# ECC_AGG_R5SS1_CORE1_ECC_AGG_R5SS1_CORE1 register map
Vendor: Texas Instruments
Peripheral module from a debugger description file (folder AM263).
Registers are 32-bit, read-write, reset 0x0 unless marked. A register's access mark holds for its fields unless they carry their own. Offsets are as the file gives them; lines under a group give offsets from that group; [hi:lo] are bit positions; {n}, {i} and the like mark numbered series; 'fields as' and 'values as' point back to an identical list; <NAME> marks a mode.

## ECC_AGG_R5SS1_CORE1_ECC_AGG_R5SS1_CORE1
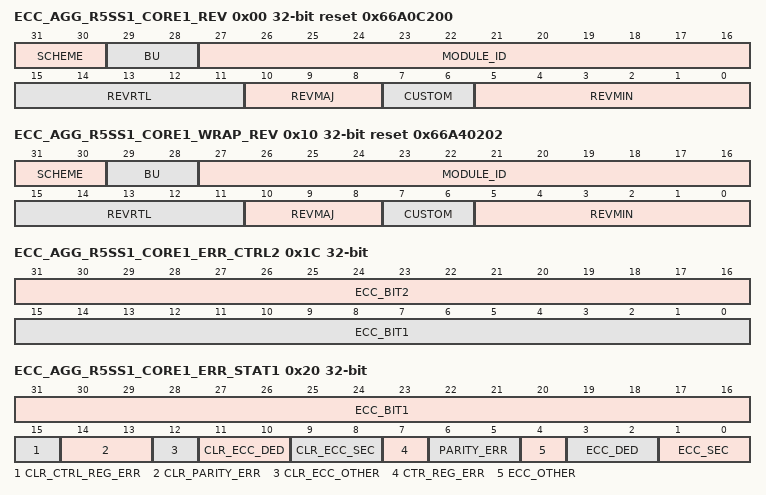
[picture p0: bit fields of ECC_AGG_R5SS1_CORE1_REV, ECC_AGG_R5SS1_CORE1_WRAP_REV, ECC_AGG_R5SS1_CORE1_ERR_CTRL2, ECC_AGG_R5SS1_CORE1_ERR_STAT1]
0x00 ECC_AGG_R5SS1_CORE1_REV ro reset 0x66A0C200
  [31:30] SCHEME
  [29:28] BU
  [27:16] MODULE_ID
  [15:11] REVRTL — RTL version
  [10:8] REVMAJ — Major version
  [7:6] CUSTOM — Custom version
  [5:0] REVMIN — Minor version
0x08 ECC_AGG_R5SS1_CORE1_VECTOR 24-bit access per field
  [24] RD_SVBUS_DONE ro — Status to indicate if read on serial VBUS is complete
  [23:16] RD_SVBUS_ADDRESS rw — Read address
  [15] RD_SVBUS rw — Write 1 to trigger a read on the serial VBUS
  [10:0] ECC_VECTOR rw — Value written to select the corresponding ECC RAM for control or status
0x0C ECC_AGG_R5SS1_CORE1_STAT 16-bit ro reset 0x1C
  [10:0] NUM_RAMS — Indicates the number of RAMS serviced by the ECC aggregator
0x10 ECC_AGG_R5SS1_CORE1_WRAP_REV ro reset 0x66A40202
  fields as ECC_AGG_R5SS1_CORE1_REV
0x14 ECC_AGG_R5SS1_CORE1_CTRL 8-bit reset 0x187
  [8] CHECK_SVBUS_TIMEOUT — check for svbus timeout errors
  [7] CHECK_PARITY — check for parity errors
  [6] ERROR_ONCE — Force Error only once
  [5] FORCE_N_ROW — Force Error on any RAM read
  [4] FORCE_DED — Force Double Bit Error
  [3] FORCE_SEC — Force Single Bit Error
  [2] ENABLE_RMW
  [1] ECC_CHECK — Enable ECC check
  [0] ECC_ENABLE — Enable ECC
0x18 ECC_AGG_R5SS1_CORE1_ERR_CTRL1
  [31:0] ECC_ROW — Row address where single or double-bit error needs to be applied. This is ignored if force_n_row is set
0x1C ECC_AGG_R5SS1_CORE1_ERR_CTRL2
  [31:16] ECC_BIT2 — Data bit that needs to be flipped if double bit error needs to be forced
  [15:0] ECC_BIT1 — Data bit that needs to be flipped when force_sec is set
0x20 ECC_AGG_R5SS1_CORE1_ERR_STAT1 access not given
  [31:16] ECC_BIT1 ro — Data bit that corresponds to the single-bit error
  [15] CLR_CTRL_REG_ERR rw — Clear control reg error Error Status, you must also re write the contorl ergister itself to clear this
  [14:13] CLR_PARITY_ERR — Clear parity Error Status (access RW DECR)
  [12] CLR_ECC_OTHER rw — Clear other Error Status
  [11:10] CLR_ECC_DED — Clear Double Bit Error Status (access RW DECR)
  [9:8] CLR_ECC_SEC — Clear Single Bit Error Status (access RW DECR)
  [7] CTR_REG_ERR rw — control register error pending, Level interrupt
  [6:5] PARITY_ERR rw — Level parity error Error Status
  [4] ECC_OTHER rw — successive single-bit errors have occurred while a writeback is still pending, Level interrupt
  [3:2] ECC_DED — Level Double Bit Error Status (access RW INCR)
  [1:0] ECC_SEC — Level Single Bit Error Status (access RW INCR)
0x24 ECC_AGG_R5SS1_CORE1_ERR_STAT2 ro
  [31:0] ECC_ROW — Row address where the single or double-bit error has occurred
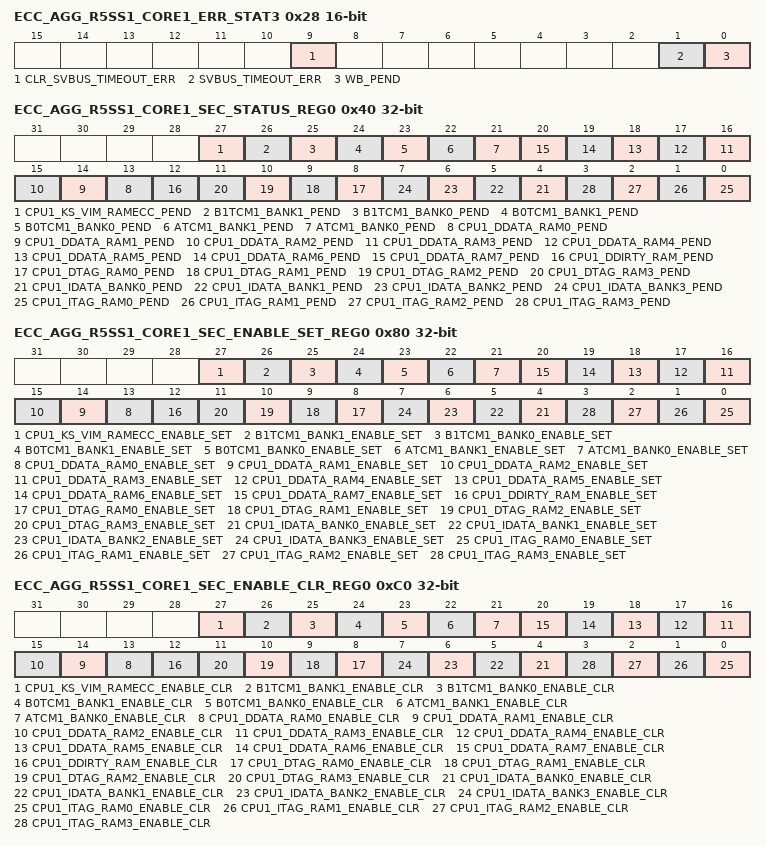
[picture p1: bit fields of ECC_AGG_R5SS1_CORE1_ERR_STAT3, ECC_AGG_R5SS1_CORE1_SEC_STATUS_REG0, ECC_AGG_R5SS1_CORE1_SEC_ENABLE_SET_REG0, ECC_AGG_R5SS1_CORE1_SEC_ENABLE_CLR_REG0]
0x28 ECC_AGG_R5SS1_CORE1_ERR_STAT3 16-bit access per field
  [9] CLR_SVBUS_TIMEOUT_ERR rw — Clear svbus timeout Error Status
  [1] SVBUS_TIMEOUT_ERR rw — Level svbus timeout error Error Status
  [0] WB_PEND ro — delayed write back pending Status
0x3C ECC_AGG_R5SS1_CORE1_SEC_EOI_REG size not given
  [0] EOI_WR — EOI Register
0x40 ECC_AGG_R5SS1_CORE1_SEC_STATUS_REG0
  [27] CPU1_KS_VIM_RAMECC_PEND — Interrupt Pending Status for cpu1_ks_vim_ramecc_pend
  [26] B1TCM1_BANK1_PEND — Interrupt Pending Status for b1tcm1_bank1_pend
  [25] B1TCM1_BANK0_PEND — Interrupt Pending Status for b1tcm1_bank0_pend
  [24] B0TCM1_BANK1_PEND — Interrupt Pending Status for b0tcm1_bank1_pend
  [23] B0TCM1_BANK0_PEND — Interrupt Pending Status for b0tcm1_bank0_pend
  [22] ATCM1_BANK1_PEND — Interrupt Pending Status for atcm1_bank1_pend
  [21] ATCM1_BANK0_PEND — Interrupt Pending Status for atcm1_bank0_pend
  [n+13] CPU1_DDATA_RAM{n}_PEND (n=0..7) — Interrupt Pending Status for cpu1_ddata_ram{n}_pend
  [12] CPU1_DDIRTY_RAM_PEND — Interrupt Pending Status for cpu1_ddirty_ram_pend
  [n+8] CPU1_DTAG_RAM{n}_PEND (n=0..3) — Interrupt Pending Status for cpu1_dtag_ram{n}_pend
  [n+4] CPU1_IDATA_BANK{n}_PEND (n=0..3) — Interrupt Pending Status for cpu1_idata_bank{n}_pend
  [n] CPU1_ITAG_RAM{n}_PEND (n=0..3) — Interrupt Pending Status for cpu1_itag_ram{n}_pend
0x80 ECC_AGG_R5SS1_CORE1_SEC_ENABLE_SET_REG0
  [27] CPU1_KS_VIM_RAMECC_ENABLE_SET — Interrupt Enable Set Register for cpu1_ks_vim_ramecc_pend
  [26] B1TCM1_BANK1_ENABLE_SET — Interrupt Enable Set Register for b1tcm1_bank1_pend
  [25] B1TCM1_BANK0_ENABLE_SET — Interrupt Enable Set Register for b1tcm1_bank0_pend
  [24] B0TCM1_BANK1_ENABLE_SET — Interrupt Enable Set Register for b0tcm1_bank1_pend
  [23] B0TCM1_BANK0_ENABLE_SET — Interrupt Enable Set Register for b0tcm1_bank0_pend
  [22] ATCM1_BANK1_ENABLE_SET — Interrupt Enable Set Register for atcm1_bank1_pend
  [21] ATCM1_BANK0_ENABLE_SET — Interrupt Enable Set Register for atcm1_bank0_pend
  [n+13] CPU1_DDATA_RAM{n}_ENABLE_SET (n=0..7) — Interrupt Enable Set Register for cpu1_ddata_ram{n}_pend
  [12] CPU1_DDIRTY_RAM_ENABLE_SET — Interrupt Enable Set Register for cpu1_ddirty_ram_pend
  [n+8] CPU1_DTAG_RAM{n}_ENABLE_SET (n=0..3) — Interrupt Enable Set Register for cpu1_dtag_ram{n}_pend
  [n+4] CPU1_IDATA_BANK{n}_ENABLE_SET (n=0..3) — Interrupt Enable Set Register for cpu1_idata_bank{n}_pend
  [n] CPU1_ITAG_RAM{n}_ENABLE_SET (n=0..3) — Interrupt Enable Set Register for cpu1_itag_ram{n}_pend
0xC0 ECC_AGG_R5SS1_CORE1_SEC_ENABLE_CLR_REG0
  [27] CPU1_KS_VIM_RAMECC_ENABLE_CLR — Interrupt Enable Clear Register for cpu1_ks_vim_ramecc_pend
  [26] B1TCM1_BANK1_ENABLE_CLR — Interrupt Enable Clear Register for b1tcm1_bank1_pend
  [25] B1TCM1_BANK0_ENABLE_CLR — Interrupt Enable Clear Register for b1tcm1_bank0_pend
  [24] B0TCM1_BANK1_ENABLE_CLR — Interrupt Enable Clear Register for b0tcm1_bank1_pend
  [23] B0TCM1_BANK0_ENABLE_CLR — Interrupt Enable Clear Register for b0tcm1_bank0_pend
  [22] ATCM1_BANK1_ENABLE_CLR — Interrupt Enable Clear Register for atcm1_bank1_pend
  [21] ATCM1_BANK0_ENABLE_CLR — Interrupt Enable Clear Register for atcm1_bank0_pend
  [n+13] CPU1_DDATA_RAM{n}_ENABLE_CLR (n=0..7) — Interrupt Enable Clear Register for cpu1_ddata_ram{n}_pend
  [12] CPU1_DDIRTY_RAM_ENABLE_CLR — Interrupt Enable Clear Register for cpu1_ddirty_ram_pend
  [n+8] CPU1_DTAG_RAM{n}_ENABLE_CLR (n=0..3) — Interrupt Enable Clear Register for cpu1_dtag_ram{n}_pend
  [n+4] CPU1_IDATA_BANK{n}_ENABLE_CLR (n=0..3) — Interrupt Enable Clear Register for cpu1_idata_bank{n}_pend
  [n] CPU1_ITAG_RAM{n}_ENABLE_CLR (n=0..3) — Interrupt Enable Clear Register for cpu1_itag_ram{n}_pend
0x13C ECC_AGG_R5SS1_CORE1_DED_EOI_REG size not given
  [0] EOI_WR — EOI Register
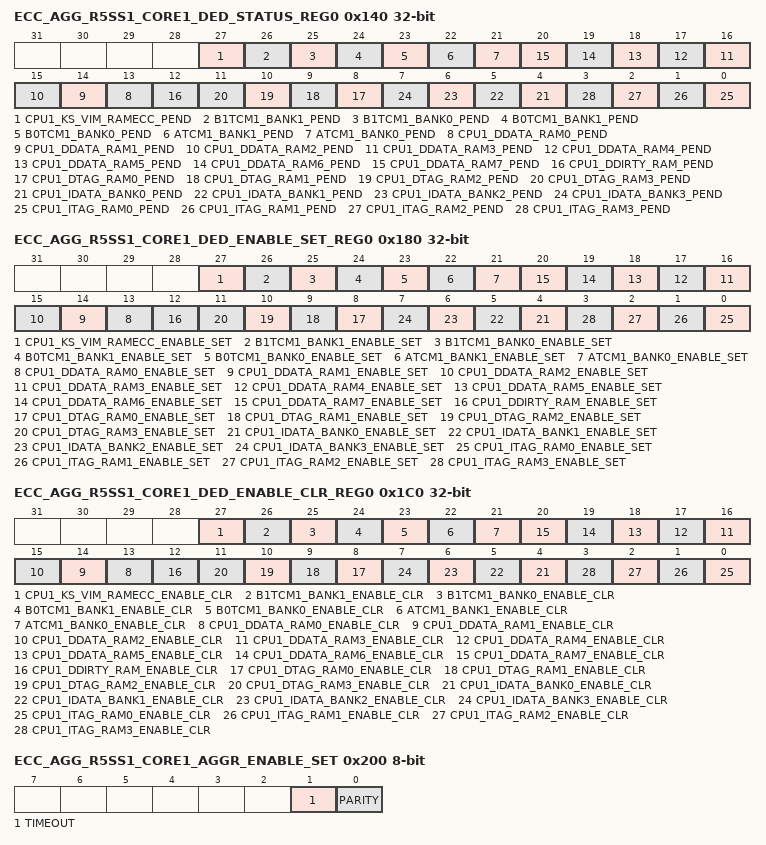
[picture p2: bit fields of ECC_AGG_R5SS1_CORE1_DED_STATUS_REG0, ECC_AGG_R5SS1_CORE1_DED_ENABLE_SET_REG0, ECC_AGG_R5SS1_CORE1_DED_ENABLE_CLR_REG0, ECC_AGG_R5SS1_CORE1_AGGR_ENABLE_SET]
0x140 ECC_AGG_R5SS1_CORE1_DED_STATUS_REG0
  fields as ECC_AGG_R5SS1_CORE1_SEC_STATUS_REG0
0x180 ECC_AGG_R5SS1_CORE1_DED_ENABLE_SET_REG0
  fields as ECC_AGG_R5SS1_CORE1_SEC_ENABLE_SET_REG0
0x1C0 ECC_AGG_R5SS1_CORE1_DED_ENABLE_CLR_REG0
  fields as ECC_AGG_R5SS1_CORE1_SEC_ENABLE_CLR_REG0
0x200 ECC_AGG_R5SS1_CORE1_AGGR_ENABLE_SET 8-bit
  [1] TIMEOUT — interrupt enable set for svbus timeout errors
  [0] PARITY — interrupt enable set for parity errors
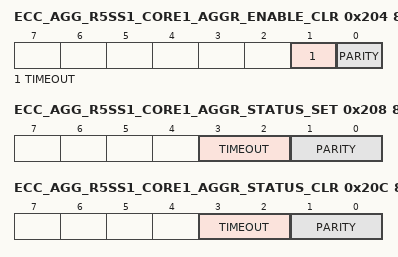
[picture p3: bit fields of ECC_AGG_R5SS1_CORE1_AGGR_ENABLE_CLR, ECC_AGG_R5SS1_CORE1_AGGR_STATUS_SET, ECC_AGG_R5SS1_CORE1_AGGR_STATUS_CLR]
0x204 ECC_AGG_R5SS1_CORE1_AGGR_ENABLE_CLR 8-bit
  [1] TIMEOUT — interrupt enable clear for svbus timeout errors
  [0] PARITY — interrupt enable clear for parity errors
0x208 ECC_AGG_R5SS1_CORE1_AGGR_STATUS_SET 8-bit access not given
  [3:2] TIMEOUT — interrupt status set for svbus timeout errors (access RW INCR)
  [1:0] PARITY — interrupt status set for parity errors (access RW INCR)
0x20C ECC_AGG_R5SS1_CORE1_AGGR_STATUS_CLR 8-bit access not given
  [3:2] TIMEOUT — interrupt status clear for svbus timeout errors (access RW DECR)
  [1:0] PARITY — interrupt status clear for parity errors (access RW DECR)
